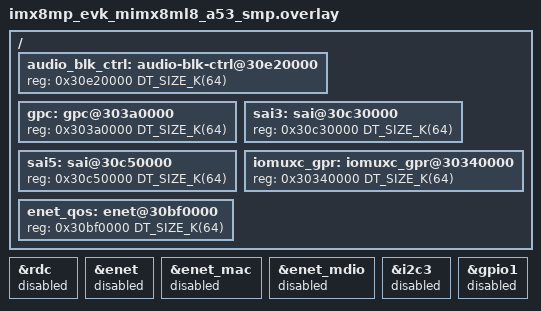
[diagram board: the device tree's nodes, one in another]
/*
 * Copyright 2024-2025 NXP
 *
 * SPDX-License-Identifier: BSD-3-Clause
 */

/ {
	audio_blk_ctrl: audio-blk-ctrl@30e20000 {
		reg = <0x30e20000 DT_SIZE_K(64)>;
	};

	gpc: gpc@303a0000 {
		reg = <0x303a0000 DT_SIZE_K(64)>;
	};

	sai3: sai@30c30000 {
		reg = <0x30c30000 DT_SIZE_K(64)>;
	};

	sai5: sai@30c50000 {
		reg = <0x30c50000 DT_SIZE_K(64)>;
	};

	iomuxc_gpr: iomuxc_gpr@30340000 {
		reg = <0x30340000 DT_SIZE_K(64)>;
	};

	enet_qos: enet@30bf0000 {
		reg = <0x30bf0000 DT_SIZE_K(64)>;
	};
};

&rdc {
	status = "disabled";
};

&enet {
	status = "disabled";
};

&enet_mac {
	status = "disabled";
};

&enet_mdio {
	status = "disabled";
};

&i2c3 {
	status = "disabled";
};

&gpio1 {
	status = "disabled";
};
